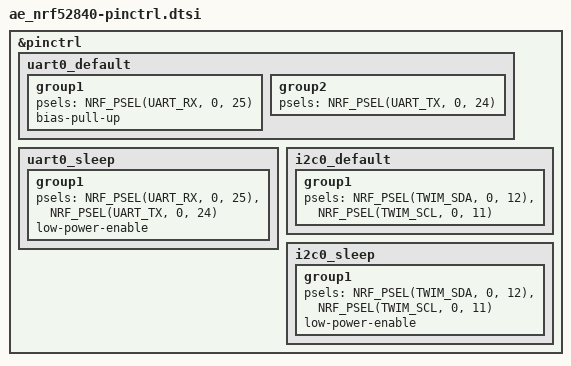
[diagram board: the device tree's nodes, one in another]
/*
 * Copyright (c) 2022 The ZMK Contributors
 * SPDX-License-Identifier: MIT
 */

&pinctrl {
    uart0_default: uart0_default {
        group1 {
            psels = <NRF_PSEL(UART_RX, 0, 25)>;
            bias-pull-up;
        };
        group2 {
            psels = <NRF_PSEL(UART_TX, 0, 24)>;
        };
    };

    uart0_sleep: uart0_sleep {
        group1 {
            psels = <NRF_PSEL(UART_RX, 0, 25)>,
                <NRF_PSEL(UART_TX, 0, 24)>;
            low-power-enable;
        };
    };

    i2c0_default: i2c0_default {
        group1 {
            psels = <NRF_PSEL(TWIM_SDA, 0, 12)>,
                <NRF_PSEL(TWIM_SCL, 0, 11)>;
        };
    };

    i2c0_sleep: i2c0_sleep {
        group1 {
            psels = <NRF_PSEL(TWIM_SDA, 0, 12)>,
                <NRF_PSEL(TWIM_SCL, 0, 11)>;
            low-power-enable;
        };
    };
};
